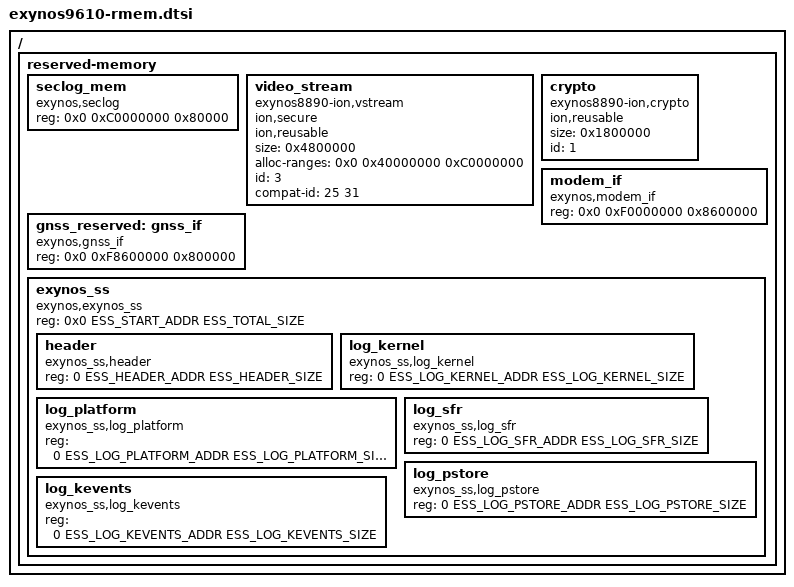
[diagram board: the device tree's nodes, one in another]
/*
 * SAMSUNG EXYNOS device tree source for reserved-memory
 *
 * Copyright (c) 2015 Samsung Electronics Co., Ltd.
 *		http://www.samsung.com
 *
 * This program is free software; you can redistribute it and/or modify
 * it under the terms of the GNU General Public License version 2 as
 * published by the Free Software Foundation.
 */

#include "../../../../../include/generated/autoconf.h"
#include <dt-bindings/soc/samsung/exynos-ss-table.h>

/memreserve/ 0xE0000000 0x1900000;
/ {
	reserved-memory {
		#address-cells = <2>;
		#size-cells = <1>;
		ranges;

		seclog_mem {
			compatible = "exynos,seclog";
			reg = <0x0 0xC0000000 0x80000>;
		};

		video_stream {
			compatible = "exynos8890-ion,vstream";
			ion,secure;
			ion,reusable;
			size = <0x4800000>;
			alloc-ranges = <0x0 0x40000000 0xC0000000>;
			id = <3>;
			compat-id = <25 31>;
		};

		crypto {
			compatible = "exynos8890-ion,crypto";
			ion,reusable;
			size = <0x1800000>;
			id = <1>;
		};

		modem_if {
			compatible = "exynos,modem_if";
			reg = <0x0 0xF0000000 0x8600000>;
		};

		gnss_reserved: gnss_if {
			compatible = "exynos,gnss_if";
			reg = <0x0 0xF8600000 0x800000>;
		};

		exynos_ss {
			compatible = "exynos,exynos_ss";
			reg = <0x0 ESS_START_ADDR ESS_TOTAL_SIZE>;
			#address-cells = <2>;
			#size-cells = <1>;
			/* If this property exist, these are modified by bootloader. */
			//bootloader;

			header {
				compatible = "exynos_ss,header";
				reg = <0 ESS_HEADER_ADDR ESS_HEADER_SIZE>;
			};
			log_kernel {
				compatible = "exynos_ss,log_kernel";
				reg = <0 ESS_LOG_KERNEL_ADDR ESS_LOG_KERNEL_SIZE>;
			};
			log_platform {
				compatible = "exynos_ss,log_platform";
				reg = <0 ESS_LOG_PLATFORM_ADDR ESS_LOG_PLATFORM_SIZE>;
			};
			log_sfr {
				compatible = "exynos_ss,log_sfr";
				reg = <0 ESS_LOG_SFR_ADDR ESS_LOG_SFR_SIZE>;
			};
			log_pstore {
				compatible = "exynos_ss,log_pstore";
				reg = <0 ESS_LOG_PSTORE_ADDR ESS_LOG_PSTORE_SIZE>;
			};
			log_kevents {
				compatible = "exynos_ss,log_kevents";
				reg = <0 ESS_LOG_KEVENTS_ADDR ESS_LOG_KEVENTS_SIZE>;
			};
		};
	};
};
